# GAP8 register map
Vendor: GreenWaves Technologies SAS; Series: GAP8; File version: 1.3.1
CPU: other r1p0, little endian, MPU, no FPU, I-cache, DTCM, false interrupt priority bits
Registers are 32-bit, read-write, reset 0x0 unless marked. A register's access mark holds for its fields unless they carry their own. Offsets are from the block's base; [hi:lo] are bit positions; 'fields as' and 'values as' point back to an identical list.

## i2s — uDMA I2S interface
Base 0x1A102400
0x00 rx_saddr_ch0 — uDMA RX I2S channel 0 buffer base address configuration register.
  [15:0] rx_saddr — I2S channel 0 RX buffer base address bitfield: - Read: returns value of the buffer pointer until transfer is finished. Else returns 0. - Write: sets RX buffer base address
0x04 rx_size_ch0 — uDMA RX I2S channel 0 buffer size configuration register.
  [16:0] rx_size — I2S channel 0 RX buffer size bitfield in bytes. (128kBytes maximum) - Read: returns remaining buffer size to transfer. - Write: sets buffer size.
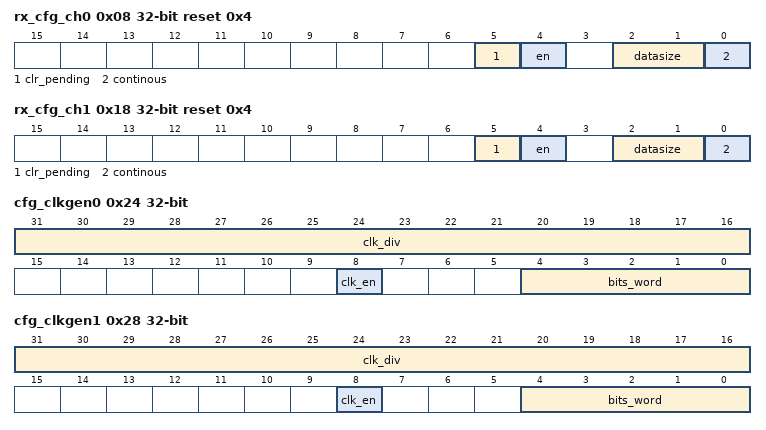
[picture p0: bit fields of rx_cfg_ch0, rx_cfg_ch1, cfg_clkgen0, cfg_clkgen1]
0x08 rx_cfg_ch0 reset 0x4 — uDMA RX I2S channel 0 stream configuration register.
  [5] clr_pending — I2S channel 0 RX Channel clear and stop transfer I2S channel 0 RX Transfer pending in queue status flag
    on write: 0=disable (feature is disabled); 1=stop and clear the on-going transfer | on read: 0=no pending transfer in the queue; 1=pending transfer in the queue
  [4] en — I2S channel 0 RX Channel enable and start transfer bitfield This signal is used also to queue a transfer if one is already ongoing.
    0=disable (feature is disabled); 1=start (enable and start the transfer)
  [2:1] datasize — RX channel transfer size used to increment uDMA I2S channel 0 RX buffer address pointer
    0=plus_1 (+1 (8 bits)); 1=plus_2 (+2 (16 bits)); 2=plus_4 (+4 (32 bits)); 3=plus_0 (+0)
  [0] continous — I2S channel 0 RX channel continuous mode bitfield At the end of the buffer transfer, the uDMA reloads the address / buffer size and starts a new transfer.
    0=disabled (feature is disabled); 1=enabled (feature is enabled)
0x10 rx_saddr_ch1 — uDMA RX I2S channel 1 buffer base address configuration register.
  [15:0] tx_saddr — I2S channel 1 RX buffer base address bitfield: - Read: returns value of the buffer pointer until transfer is finished. Else returns 0. - Write: sets RX buffer base address
0x14 rx_size_ch1 — uDMA RX I2S channel 1 buffer size configuration register.
  [16:0] tx_size — I2S channel 1 RX buffer size bitfield in bytes. (128kBytes maximum) - Read: returns remaining buffer size to transfer. - Write: sets buffer size.
0x18 rx_cfg_ch1 reset 0x4 — uDMA RX I2S channel 1 stream configuration register.
  [5] clr_pending — I2S channel 1 RX Channel clear and stop transfer I2S channel 1 RX Transfer pending in queue status flag
    values as rx_cfg_ch0.clr_pending
  [4] en — I2S channel 1 RX Channel enable and start transfer bitfield This signal is used also to queue a transfer if one is already ongoing.
    values as rx_cfg_ch0.en
  [2:1] datasize — RX channel transfer size used to increment uDMA I2S channel 1 RX buffer address pointer
    values as rx_cfg_ch0.datasize
  [0] continous — I2S channel 1 RX channel continuous mode bitfield At the end of the buffer transfer, the uDMA reloads the address / buffer size and starts a new transfer.
    values as rx_cfg_ch0.continous
0x20 cfg_ext — I2S external clock configuration register.
  [4:0] ext_bits_word — External clock word length in bits bitfield. The value is (num bits - 1).
0x24 cfg_clkgen0 — I2S clock and WS generator 0 configuration register.
  [31:16] clk_div — Clock generator 0 clock divider related to SoC clock frequency.
  [8] clk_en — Clock generator 0 enable bitfield
    0=disabled (feature is disabled); 1=enabled. Clock and WS signal are generated.
  [4:0] bits_word — Clock generator 0 word length in bits bitfield. The value is (num bits - 1).
0x28 cfg_clkgen1 — I2S clock and WS generator 1 configuration register.
  [31:16] clk_div — Clock generator 1 clock divider related to SoC clock frequency.
  [8] clk_en — Clock generator 1 enable bitfield
    values as cfg_clkgen0.clk_en
  [4:0] bits_word — Clock generator 1 word length in bits bitfield. The value is (num bits - 1).
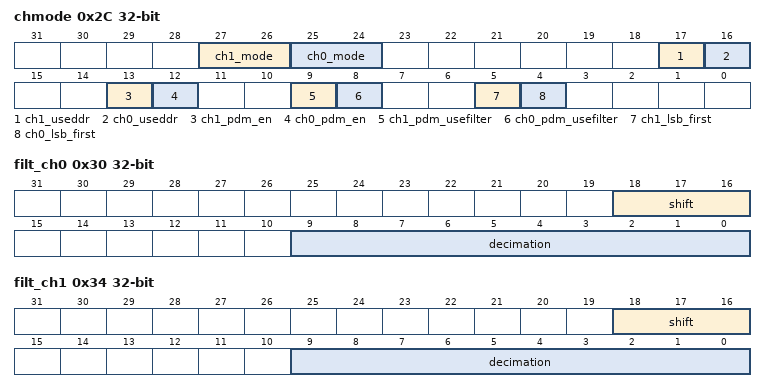
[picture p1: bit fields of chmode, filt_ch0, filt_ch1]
0x2C chmode — I2S channels mode configuration register.
  [27:26] ch1_mode — I2S channel 1 clock/WS mode configuration bitfield
    0=clock_gen_0 (use clock generator 0 (clock and WS generated by clkgen)); 1=clock_gen_1 (use clock generator 1 (clock and WS generated by clkgen)); 2=ext clock int ws - use external clock but internal generated WS by clock generator 0; 3=ext clock ext ws - use external clock and external WS
  [25:24] ch0_mode — I2S channel 0 clock/WS mode configuration bitfield
    values as ch1_mode
  [17] ch1_useddr — I2S channel 1 DDR mode activation bitfield
    values as rx_cfg_ch0.continous
  [16] ch0_useddr — I2S channel 0 DDR mode activation bitfield
    values as rx_cfg_ch0.continous
  [13] ch1_pdm_en — I2S channel 1 PDM demodulation activation bitfield
    values as rx_cfg_ch0.continous
  [12] ch0_pdm_en — I2S channel 0 PDM demodulation activation bitfield
    values as rx_cfg_ch0.continous
  [9] ch1_pdm_usefilter — I2S channel 1 PDM filter activation bitfield
    values as rx_cfg_ch0.continous
  [8] ch0_pdm_usefilter — I2S channel 0 PDM filter activation bitfield
    values as rx_cfg_ch0.continous
  [5] ch1_lsb_first — I2S channel 1 LSB first configuration for word serialization bitfield
    0=msb_first (set to MSB first); 1=lsb_first (set to LSB first)
  [4] ch0_lsb_first — I2S channel 0 LSB first configuration for word serialization bitfield
    values as ch1_lsb_first
0x30 filt_ch0 — I2S channel 0 filtering configuration register.
  [18:16] shift — I2S channel 0 PDM filter normalisation right shift value bitfield.
  [9:0] decimation — I2S channel 0 PDM filter decimation value bitfield.
0x34 filt_ch1 — I2S channel 1 filtering configuration register.
  [18:16] shift — I2S channel 1 PDM filter normalisation right shift value bitfield.
  [9:0] decimation — I2S channel 1 PDM filter decimation value bitfield.
